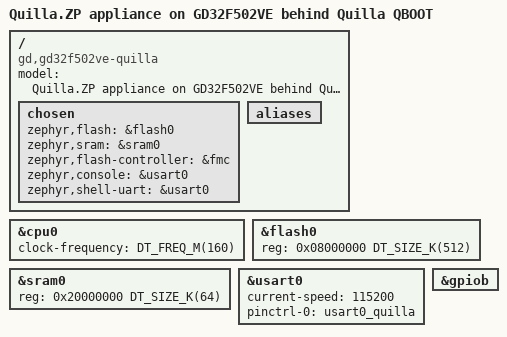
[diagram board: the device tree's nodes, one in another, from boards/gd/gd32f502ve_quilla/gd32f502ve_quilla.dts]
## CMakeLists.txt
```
# Copyright (c) 2026, JiChiRen Info. Tech.
# All rights reserved.
#
# Redistribution and use in source and binary forms, with or without
# modification, are permitted provided that the conditions of the BSD-3
# license referenced in the project LICENSE file are met.

cmake_minimum_required(VERSION 3.20.0)

find_package(Zephyr REQUIRED HINTS $ENV{ZEPHYR_BASE})
project(quilla_zp LANGUAGES C)

# Each Quilla-side capability is a separate translation unit registered
# through Zephyr's own mechanisms (SHELL_CMD_REGISTER, SYS_INIT, Kconfig,
# devicetree). Nothing is added to the upstream Zephyr tree.
target_sources(app PRIVATE
  src/main.c
  src/quilla_shell.c
  src/quilla_meta.c
  src/quilla_secver.c
  src/led.c
)

# quilla-version.h is the single source for the signed security version
# (QUILLA_APP_SECURITY_VERSION) and the QAV1 magic; it lives in the Quilla
# subtree shipped alongside this appliance. No Zephyr Kconfig knob for the
# version: override it per build with -DQUILLA_APP_SECURITY_VERSION=<n>.
target_include_directories(app PRIVATE
  src
  ${CMAKE_CURRENT_SOURCE_DIR}/../quilla/os/sys
)

# The QAV1 security-version record must sit at a fixed flash address because
# QBOOT reads it without a symbol table. A ROM_START linker snippet is the
# standard Zephyr way to reserve that slot; see app/linker/quilla-secver.ld.
# SORT_KEY places it after Zephyr's own vector-table snippets.
zephyr_linker_sources(ROM_START SORT_KEY 0x3secver linker/quilla-secver.ld)
```

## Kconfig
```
# Copyright (c) 2026, JiChiRen Info. Tech.
# All rights reserved.
# SPDX-License-Identifier: BSD-3-Clause

menu "Quilla.ZP appliance"

# The firmware security version is NOT configured here: it comes from the
# shared Quilla header quilla/os/sys/quilla-version.h as
# QUILLA_APP_SECURITY_VERSION (overridable per build with a -D define), so
# QAPP, QBOOT and this appliance all use one version source.

config QUILLA_ZP_APP_NAME
	string "Application name printed in the [QAPP] banner"
	default "Quilla.ZP"

config QUILLA_ZP_APP_VERSION
	string "Application version string"
	default "V1.0.0001"

config QUILLA_ZP_META_BASE
	hex "META region base address"
	default 0x08006000

config QUILLA_ZP_META_SIZE
	hex "META region size"
	default 0x1000

config QUILLA_ZP_APP_START
	hex "APP region base address"
	default 0x08007000

config QUILLA_ZP_SECVER_OFFSET
	hex "Security-version record offset from APP start"
	default 0x400

config QUILLA_ZP_LED_BEAT_MS
	int "LED heart-beat period in milliseconds (0 disables)"
	default 1000

endmenu

# An application Kconfig replaces the Zephyr root Kconfig, so the upstream
# tree must be sourced explicitly. Without this line no CONFIG_* symbol
# outside this file exists and the build aborts with "undefined symbol".
source "Kconfig.zephyr"
```

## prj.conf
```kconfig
# Copyright (c) 2026, JiChiRen Info. Tech.
# All rights reserved.
# SPDX-License-Identifier: BSD-3-Clause
#
# Quilla.ZP application configuration.

# ---- Console / Quilla APP shell -------------------------------------------
# The console UART is chosen in app/boards/gd/gd32f502ve_quilla/*.dts; it is
# USART0 / PB6-PB7 / 115200, the same wiring QBOOT uses on this board.
CONFIG_CONSOLE=y
CONFIG_UART_CONSOLE=y
CONFIG_SERIAL=y
CONFIG_SHELL=y
CONFIG_SHELL_BACKEND_SERIAL=y
# The Quilla host updater probes with a bare "part" line and matches "app1"
# in the reply. A plain prompt keeps the line parser free of ANSI escapes.
CONFIG_SHELL_PROMPT_UART="> "
CONFIG_SHELL_VT100_COLORS=n
CONFIG_SHELL_VT100_COMMANDS=n
CONFIG_SHELL_WILDCARD=n
CONFIG_SHELL_HISTORY=n

# ---- Flash driver (META record writer) ------------------------------------
CONFIG_FLASH=y

# ---- GPIO / LED heart-beat -------------------------------------------------
CONFIG_GPIO=y

# ---- Boot handover ---------------------------------------------------------
# Quilla QBOOT owns the boot policy. The APP vector table must be at
# 0x08007000 exactly (QBOOT reads MSP/reset from there and sets VTOR), so
# link with an explicit flash offset and reserve no image header.
CONFIG_BOOTLOADER_MCUBOOT=n
CONFIG_ROM_START_OFFSET=0
CONFIG_USE_DT_CODE_PARTITION=n
CONFIG_FLASH_LOAD_OFFSET=0x7000
CONFIG_FLASH_LOAD_SIZE=0x79000
# The QAV1 linker snippet is injected via snippets-rom-start.ld, which is
# consumed by the LD template path (the CMake linker generator does not
# include it). Pin the template so the section cannot silently disappear.
CONFIG_LD_LINKER_TEMPLATE=y

# ---- Runtime ---------------------------------------------------------------
CONFIG_MAIN_STACK_SIZE=2048
CONFIG_PRINTK=y
# sys_reboot() is only compiled when CONFIG_REBOOT is set (lib/os/Kconfig).
CONFIG_REBOOT=y
CONFIG_LOG=n
```

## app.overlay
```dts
/*
 * Copyright (c) 2026, JiChiRen Info. Tech.
 * All rights reserved.
 * SPDX-License-Identifier: BSD-3-Clause
 *
 * Optional board wiring that is not part of the QBOOT contract.
 *
 * The QBOOT console (USART0 / PB6-PB7 / 115200), the flash geometry and the
 * core clock are fixed in the out-of-tree board definition under
 * app/boards/gd/gd32f502ve_quilla/. Nothing here may change them.
 *
 * To enable the LED heart-beat thread, add a led0 alias matching the LED on
 * the actual board, for example:
 *
 *   / {
 *       leds {
 *           compatible = "gpio-leds";
 *           led0: led_0 {
 *               gpios = <&gpiob 2 GPIO_ACTIVE_LOW>;
 *               label = "User LED";
 *           };
 *       };
 *
 *       aliases { led0 = &led0; };
 *   };
 *
 * Without led0 the application still builds and runs: the shell and the
 * QIAP handover remain fully available, and the LED thread is not created.
 */

/* Keep the overlay a valid devicetree fragment even when nothing is added. */
/ {
};
```

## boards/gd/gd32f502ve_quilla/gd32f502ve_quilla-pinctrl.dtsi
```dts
/*
 * Copyright (c) 2026, JiChiRen Info. Tech.
 * All rights reserved.
 * SPDX-License-Identifier: BSD-3-Clause
 *
 * USART0 remapped to PB6 (TX) / PB7 (RX), AF0 -- identical to QBOOT's
 * arch/cpu/arm/gd32f502ve/shellport.c binding. The pinmux macros come from
 * the hal_gigadevice module pulled by `west update`.
 */

#include <dt-bindings/pinctrl/gd32f503v(g-e-c)xx-pinctrl.h>

&pinctrl {
	usart0_quilla: usart0_quilla {
		group1 {
			pinmux = <USART0_TX_PB6>, <USART0_RX_PB7>;
			bias-pull-up;
		};
	};
};
```

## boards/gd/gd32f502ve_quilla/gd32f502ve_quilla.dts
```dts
/*
 * Copyright (c) 2026, JiChiRen Info. Tech.
 * All rights reserved.
 * SPDX-License-Identifier: BSD-3-Clause
 *
 * Out-of-tree board for the GD32F502VE target used by Quilla QBOOT.
 * The upstream gd32f50x SoC description is reused; this file overrides the
 * part-specific flash/SRAM sizes and the core clock, and binds the console
 * to the same USART0 / PB6-PB7 / 115200 wiring QBOOT uses.
 */

/dts-v1/;

#include <gd/gd32f50x/gd32f503vg.dtsi>
#include "gd32f502ve_quilla-pinctrl.dtsi"

/ {
	model = "Quilla.ZP appliance on GD32F502VE behind Quilla QBOOT";
	compatible = "gd,gd32f502ve-quilla";

	chosen {
		zephyr,flash = &flash0;
		zephyr,sram = &sram0;
		zephyr,flash-controller = &fmc;
		zephyr,console = &usart0;
		zephyr,shell-uart = &usart0;
	};

	aliases {
		/* led0 is intentionally not defined here: the reference board's LED
		 * pin is not part of the QBOOT contract. Add a led0 alias in
		 * app.overlay to enable the heart-beat thread. */
	};
};

/* GD32F502VE: 512 KiB Flash / 64 KiB SRAM, 160 MHz (8 MHz HXTAL -> PLL).
 * QBOOT leaves the RCC configured at 160 MHz when it jumps; declaring the
 * same frequency here keeps Zephyr's clock driver and UART baud derivation
 * consistent with the inherited clock tree. */
&cpu0 {
	clock-frequency = <DT_FREQ_M(160)>;
};

&flash0 {
	reg = <0x08000000 DT_SIZE_K(512)>;
};

&sram0 {
	reg = <0x20000000 DT_SIZE_K(64)>;
};

&usart0 {
	status = "okay";
	current-speed = <115200>;
	pinctrl-0 = <&usart0_quilla>;
	pinctrl-names = "default";
};

&gpiob {
	status = "okay";
};
```

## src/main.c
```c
/*
 * Copyright (c) 2026, JiChiRen Info. Tech.
 * All rights reserved.
 *
 * Redistribution and use in source and binary forms, with or without
 * modification, are permitted provided that the conditions of the BSD-3
 * license referenced in the project LICENSE file are met.
 *
 * This file is part of the Quilla.ZP appliance.
 */

#include <zephyr/kernel.h>

/*
 * Intentionally minimal. Every capability of this appliance is registered by
 * Zephyr itself:
 *
 *   quilla_shell.c  SHELL_CMD_REGISTER (part / version / swqboot)
 *                   SYS_INIT           (banner)
 *   led.c           K_THREAD_DEFINE   (LED heart-beat, optional)
 *   quilla_secver.c section attribute + ROM_START linker snippet (QAV1)
 *   quilla_meta.c   flash API, invoked only by the swqboot command
 *
 * main() only keeps the main thread alive; it must not accumulate unrelated
 * features, and it must never include a Quilla header.
 */
int main(void)
{
	while (true) {
		k_sleep(K_SECONDS(60));
	}
}
```

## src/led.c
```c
/*
 * Copyright (c) 2026, JiChiRen Info. Tech.
 * All rights reserved.
 *
 * Redistribution and use in source and binary forms, with or without
 * modification, are permitted provided that the conditions of the BSD-3
 * license referenced in the project LICENSE file are met.
 *
 * This file is part of the Quilla.ZP appliance.
 */

#include <zephyr/device.h>
#include <zephyr/devicetree.h>
#include <zephyr/drivers/gpio.h>
#include <zephyr/kernel.h>

/*
 * Zephyr's static thread registration replaces the Quilla QAPP Contiki
 * process / FreeRTOS task: the LED heart-beat is a K_THREAD_DEFINE entry, and
 * the LED itself comes from the devicetree "led0" alias. Adding an alias in
 * app.overlay is enough to enable the thread; no source change required.
 *
 * This file owns the LED only. It does not touch the console, META or secver.
 */

#if DT_NODE_EXISTS(DT_ALIAS(led0))

static const struct gpio_dt_spec led = GPIO_DT_SPEC_GET(DT_ALIAS(led0), gpios);

static void led_thread(void *unused1, void *unused2, void *unused3)
{
	ARG_UNUSED(unused1);
	ARG_UNUSED(unused2);
	ARG_UNUSED(unused3);

	if (!gpio_is_ready_dt(&led)) {
		return;
	}
	if (gpio_pin_configure_dt(&led, GPIO_OUTPUT_ACTIVE) != 0) {
		return;
	}

	while (true) {
		gpio_pin_toggle_dt(&led);
		k_msleep(CONFIG_QUILLA_ZP_LED_BEAT_MS);
	}
}

K_THREAD_DEFINE(quilla_zp_led_tid, 512, led_thread, NULL, NULL, NULL,
		K_LOWEST_APPLICATION_THREAD_PRIO, 0, 0);

#endif /* DT_NODE_EXISTS(DT_ALIAS(led0)) */
```

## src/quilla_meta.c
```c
/*
 * Copyright (c) 2026, JiChiRen Info. Tech.
 * All rights reserved.
 *
 * Redistribution and use in source and binary forms, with or without
 * modification, are permitted provided that the conditions of the BSD-3
 * license referenced in the project LICENSE file are met.
 *
 * This file is part of the Quilla.ZP appliance.
 */

#include "quilla_meta.h"

#include <errno.h>
#include <string.h>

#include <zephyr/device.h>
#include <zephyr/devicetree.h>
#include <zephyr/drivers/flash.h>
#include <zephyr/kernel.h>
#include <zephyr/sys/util.h>

/*
 * APP-side META writer. QBOOT owns the boot policy; the appliance is only
 * allowed to append one record changing the interaction flag. Every field
 * that belongs to QBOOT (manifest, seal, anti-rollback floor) is inherited
 * unchanged, so an upgrade request cannot erase the factory manifest.
 *
 * The record layout, magics and CRC are binary-compatible with
 * quilla-qboot-meta.c. No Quilla header is included: the two images share
 * only a flash contract.
 */

#define QZP_META_RECORD_SIZE 256U
#define QZP_META_SLOT_SIZE   (CONFIG_QUILLA_ZP_META_SIZE / 2U)
#define QZP_META_SLOTS       2U
#define QZP_REC_PER_SLOT     (QZP_META_SLOT_SIZE / QZP_META_RECORD_SIZE)

#define QZP_META_BLK_MAGIC  0x514D544CU /* "QMTL" */
#define QZP_MANI_BLK_MAGIC  0x514D4631U /* "QMF1" */
#define QZP_MANI_BLK_OFF    64U
#define QZP_MANI_BLK_SIZE   128U

#define QZP_OFF_MAGIC       0U
#define QZP_OFF_SEQ         4U
#define QZP_OFF_FLAG        8U
#define QZP_OFF_FLOOR       12U
#define QZP_OFF_CRC         52U

#define QZP_MANI_OFF_MAGIC     0U
#define QZP_MANI_OFF_VERSION   4U
#define QZP_MANI_OFF_IMAGE_LEN 8U
#define QZP_MANI_OFF_CRC       108U

/* The GD32 bank0 erase page is 2 KiB, i.e. exactly one META slot. QBOOT never
 * erases the active slot; only the standby slot is erased. */
#define QZP_ERASE_PAGE_SIZE 2048U

BUILD_ASSERT(QZP_META_SLOT_SIZE == QZP_ERASE_PAGE_SIZE,
	     "META slot must equal one GD32 flash erase page");
BUILD_ASSERT((CONFIG_QUILLA_ZP_META_BASE % QZP_ERASE_PAGE_SIZE) == 0,
	     "META base must be erase-page aligned");

static const struct device *const flash_dev =
	DEVICE_DT_GET(DT_CHOSEN(zephyr_flash_controller));

/* uint32_t storage keeps the programming buffer naturally aligned for the
 * GD32 FMC word-program path. */
static uint32_t s_best_words[QZP_META_RECORD_SIZE / 4U];
static uint32_t s_work_words[QZP_META_RECORD_SIZE / 4U];

static uint32_t rd32(const uint8_t *p)
{
	return (uint32_t)p[0] | ((uint32_t)p[1] << 8) |
	       ((uint32_t)p[2] << 16) | ((uint32_t)p[3] << 24);
}

static void wr32(uint8_t *p, uint32_t v)
{
	p[0] = (uint8_t)(v >> 0);
	p[1] = (uint8_t)(v >> 8);
	p[2] = (uint8_t)(v >> 16);
	p[3] = (uint8_t)(v >> 24);
}

/* IEEE 802.3 CRC-32, reflected polynomial 0xEDB88320. Bit-identical to
 * QBOOT's meta_crc32 and to Zephyr's crc32_ieee(); implemented locally so the
 * appliance does not depend on the CRC Kconfig driver selection. */
static uint32_t crc32_ieee(const uint8_t *p, uint32_t len)
{
	uint32_t crc = 0xFFFFFFFFU;

	for (uint32_t i = 0U; i < len; i++) {
		crc ^= p[i];
		for (uint32_t j = 0U; j < 8U; j++) {
			crc = (crc & 1U) ? ((crc >> 1U) ^ 0xEDB88320U) : (crc >> 1U);
		}
	}
	return crc ^ 0xFFFFFFFFU;
}

/* Zephyr flash API offsets are relative to the flash base, while the QBOOT
 * partition constants are absolute addresses. */
static off_t flash_offset(uint32_t abs_addr)
{
	return (off_t)(abs_addr - DT_REG_ADDR(DT_CHOSEN(zephyr_flash)));
}

static int meta_read(uint32_t abs_addr, uint8_t *dst, size_t len)
{
	return flash_read(flash_dev, flash_offset(abs_addr), dst, len);
}

static int meta_erase_slot(uint32_t abs_addr)
{
	return flash_erase(flash_dev, flash_offset(abs_addr), QZP_META_SLOT_SIZE);
}

static uint32_t record_seq(uint32_t abs_addr, uint8_t *scratch)
{
	if (meta_read(abs_addr, scratch, QZP_META_RECORD_SIZE) != 0) {
		return 0U;
	}
	if (rd32(scratch + QZP_OFF_MAGIC) != QZP_META_BLK_MAGIC) {
		return 0U;
	}
	if (crc32_ieee(scratch, QZP_OFF_CRC) != rd32(scratch + QZP_OFF_CRC)) {
		return 0U;
	}
	/* seq 0 is the "empty record" sentinel. */
	return rd32(scratch + QZP_OFF_SEQ);
}

static bool manifest_valid(const uint8_t *rec)
{
	const uint8_t *p = rec + QZP_MANI_BLK_OFF;

	if (rd32(p + QZP_MANI_OFF_MAGIC) != QZP_MANI_BLK_MAGIC) {
		return false;
	}
	return crc32_ieee(p, QZP_MANI_OFF_CRC) == rd32(p + QZP_MANI_OFF_CRC);
}

static void build_empty_manifest(uint8_t *rec)
{
	uint8_t *p = rec + QZP_MANI_BLK_OFF;

	memset(p, 0xFFU, QZP_MANI_BLK_SIZE);
	wr32(p + QZP_MANI_OFF_MAGIC, QZP_MANI_BLK_MAGIC);
	wr32(p + QZP_MANI_OFF_VERSION, 0U);
	wr32(p + QZP_MANI_OFF_IMAGE_LEN, 0U);
	wr32(p + QZP_MANI_OFF_CRC, crc32_ieee(p, QZP_MANI_OFF_CRC));
}

static bool region_erased(uint32_t abs_addr, size_t len)
{
	uint8_t buf[QZP_META_RECORD_SIZE];

	if (meta_read(abs_addr, buf, len) != 0) {
		return false;
	}
	for (size_t i = 0U; i < len; i++) {
		if (buf[i] != 0xFFU) {
			return false;
		}
	}
	return true;
}

int quilla_zp_meta_set_flag(uint32_t flag)
{
	uint8_t *best = (uint8_t *)s_best_words;
	uint8_t *work = (uint8_t *)s_work_words;
	uint32_t head[QZP_META_SLOTS] = { 0U, 0U };
	uint32_t best_seq = 0U;
	uint8_t best_slot = 0U;
	bool found = false;
	uint32_t slot_base;
	uint32_t target;
	uint32_t new_seq;
	int rc;

	if (!device_is_ready(flash_dev)) {
		return -ENODEV;
	}

	/* Scan both slots; the highest sequence is authoritative. */
	for (uint8_t slot = 0U; slot < QZP_META_SLOTS; slot++) {
		for (uint32_t idx = 0U; idx < QZP_REC_PER_SLOT; idx++) {
			uint32_t addr = CONFIG_QUILLA_ZP_META_BASE +
					((uint32_t)slot * QZP_META_SLOT_SIZE) +
					(idx * QZP_META_RECORD_SIZE);
			uint32_t seq = record_seq(addr, work);

			if (seq == 0U) {
				break;
			}
			head[slot] = idx + 1U;
			if (!found || (seq > best_seq)) {
				best_seq = seq;
				best_slot = slot;
				found = true;
				memcpy(best, work, QZP_META_RECORD_SIZE);
			}
		}
	}

	uint8_t active = found ? best_slot : 0U;
	new_seq = best_seq + 1U; /* empty store -> first record has seq 1 */

	/* Active slot full, or its write head is not blank: switch to the
	 * standby slot and erase it. The authoritative record lives in the
	 * other slot, so a power loss here cannot destroy the only copy. */
	bool switch_needed = head[active] >= QZP_REC_PER_SLOT;
	if (!switch_needed) {
		slot_base = CONFIG_QUILLA_ZP_META_BASE +
			    ((uint32_t)active * QZP_META_SLOT_SIZE);
		target = slot_base + head[active] * QZP_META_RECORD_SIZE;
		switch_needed = !region_erased(target, QZP_META_RECORD_SIZE);
	}
	if (switch_needed) {
		uint8_t other = (uint8_t)(1U - (uint32_t)active);

		rc = meta_erase_slot(CONFIG_QUILLA_ZP_META_BASE +
				     ((uint32_t)other * QZP_META_SLOT_SIZE));
		if (rc != 0) {
			return rc;
		}
		active = other;
		head[active] = 0U;
	}

	slot_base = CONFIG_QUILLA_ZP_META_BASE +
		    ((uint32_t)active * QZP_META_SLOT_SIZE);
	target = slot_base + head[active] * QZP_META_RECORD_SIZE;

	/* Compose the record: inherit every field, change only seq and flag. */
	if (found) {
		memcpy(work, best, QZP_META_RECORD_SIZE);
	} else {
		memset(work, 0xFFU, QZP_META_RECORD_SIZE);
		memset(work + QZP_OFF_FLOOR, 0U, QZP_OFF_CRC - QZP_OFF_FLOOR);
	}
	wr32(work + QZP_OFF_MAGIC, QZP_META_BLK_MAGIC);
	wr32(work + QZP_OFF_SEQ, new_seq);
	wr32(work + QZP_OFF_FLAG, flag);
	wr32(work + QZP_OFF_CRC, crc32_ieee(work, QZP_OFF_CRC));

	if (!found || !manifest_valid(work)) {
		build_empty_manifest(work);
	}

	/* Program-only append into erased cells; no erase of the active slot. */
	rc = flash_write(flash_dev, flash_offset(target), work,
			 QZP_META_RECORD_SIZE);
	if (rc != 0) {
		return rc;
	}

	/* Re-read using QBOOT's own acceptance rules. */
	if (record_seq(target, best) != new_seq) {
		return -EIO;
	}
	if (rd32(best + QZP_OFF_FLAG) != flag) {
		return -EIO;
	}
	return 0;
}
```

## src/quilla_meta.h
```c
/*
 * Copyright (c) 2026, JiChiRen Info. Tech.
 * All rights reserved.
 *
 * Redistribution and use in source and binary forms, with or without
 * modification, are permitted provided that the conditions of the BSD-3
 * license referenced in the project LICENSE file are met.
 *
 * This file is part of the Quilla.ZP appliance.
 */

#ifndef QUILLA_ZP_META_H_
#define QUILLA_ZP_META_H_

#include <stdint.h>

/* Values are defined by Quilla's quilla-qboot-flag.h. They are duplicated
 * here (not included) so the appliance has no Quilla header dependency. */
#define QUILLA_ZP_FLAG_APP1  0x00000001U
#define QUILLA_ZP_FLAG_QIAP  0x00000002U
#define QUILLA_ZP_FLAG_QBOOT 0x00000003U

/*
 * Append a META record carrying the requested flag, keeping the manifest,
 * seal and anti-rollback floor inherited from the newest valid record.
 * Returns 0 on success, negative errno on flash failure. A failure is a
 * failed commit: the caller must NOT reboot into the upgrade.
 */
int quilla_zp_meta_set_flag(uint32_t flag);

#endif /* QUILLA_ZP_META_H_ */
```

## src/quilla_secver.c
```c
/*
 * Copyright (c) 2026, JiChiRen Info. Tech.
 * All rights reserved.
 *
 * Redistribution and use in source and binary forms, with or without
 * modification, are permitted provided that the conditions of the BSD-3
 * license referenced in the project LICENSE file are met.
 *
 * This file is part of the Quilla.ZP appliance.
 */

#include "quilla_secver.h"
#include "quilla-version.h"

#include <zephyr/toolchain.h>

/*
 * Owns the QAV1 region and nothing else. The section name is consumed by
 * app/linker/quilla-secver.ld. Both the magic and the version come from the
 * shared Quilla header (single source for QAPP, QBOOT and this appliance);
 * the version is never supplied by the host updater.
 */
const quilla_zp_secver_t quilla_zp_secver
	Z_GENERIC_SECTION(.quilla_secver) __used = {
	.magic = QUILLA_APP_SECVER_MAGIC_U32,
	.version = QUILLA_APP_SECURITY_VERSION,
};
```

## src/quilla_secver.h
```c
/*
 * Copyright (c) 2026, JiChiRen Info. Tech.
 * All rights reserved.
 *
 * Redistribution and use in source and binary forms, with or without
 * modification, are permitted provided that the conditions of the BSD-3
 * license referenced in the project LICENSE file are met.
 *
 * This file is part of the Quilla.ZP appliance.
 */

#ifndef QUILLA_ZP_SECVER_H_
#define QUILLA_ZP_SECVER_H_

#include <stdint.h>

/*
 * QBOOT's anti-rollback gate reads an 8-byte record at a FIXED flash address
 * (APP_START + 0x400) without any symbol table. The layout below is defined
 * locally in the appliance: including any Quilla header here would couple the
 * two images.
 *
 * This record sits inside the signed image, so its version cannot be changed
 * without the private key.
 */
/* The magic and version values come from the shared Quilla header
 * quilla-version.h (QUILLA_APP_SECVER_MAGIC_U32 / QUILLA_APP_SECURITY_VERSION),
 * included by quilla_secver.c; only the record layout is declared locally so
 * the appliance stays independent of Quilla's headers for its type
 * definitions. */

typedef struct {
	uint32_t magic;
	uint32_t version;
} quilla_zp_secver_t;

/*
 * Zephyr-native placement: the variable is emitted into a dedicated input
 * section, and app/linker/quilla-secver.ld (registered through
 * zephyr_linker_sources(ROM_START ...)) pins that section to the absolute
 * address QBOOT reads. Do not move this definition into main.c.
 */
extern const quilla_zp_secver_t quilla_zp_secver;

#endif /* QUILLA_ZP_SECVER_H_ */
```

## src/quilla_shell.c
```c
/*
 * Copyright (c) 2026, JiChiRen Info. Tech.
 * All rights reserved.
 *
 * Redistribution and use in source and binary forms, with or without
 * modification, are permitted provided that the conditions of the BSD-3
 * license referenced in the project LICENSE file are met.
 *
 * This file is part of the Quilla.ZP appliance.
 */

#include "quilla_meta.h"

#include <errno.h>

#include <zephyr/init.h>
#include <zephyr/kernel.h>
#include <zephyr/shell/shell.h>
#include <zephyr/sys/printk.h>
#include <zephyr/sys/reboot.h>

/*
 * The Quilla APP shell, registered as a Zephyr shell command set. The host
 * updater talks to this text protocol: it probes with "part" and expects a
 * line containing "app1", then sends "swqboot" to park the device in QBOOT.
 *
 * Zephyr's own shell already provides "help" and "kernel"; Quilla's shell
 * provides "part", "kernel" and registered APP commands. Only the two
 * protocol-facing commands are added here, each with SHELL_CMD_REGISTER.
 */

static int cmd_part(const struct shell *sh, size_t argc, char **argv)
{
	ARG_UNUSED(argc);
	ARG_UNUSED(argv);

	shell_print(sh, "app1");
	return 0;
}

static int cmd_version(const struct shell *sh, size_t argc, char **argv)
{
	ARG_UNUSED(argc);
	ARG_UNUSED(argv);

	shell_print(sh, "[QAPP] " CONFIG_QUILLA_ZP_APP_NAME " "
			 CONFIG_QUILLA_ZP_APP_VERSION);
	return 0;
}

static int cmd_swqboot(const struct shell *sh, size_t argc, char **argv)
{
	int rc;

	ARG_UNUSED(argc);
	ARG_UNUSED(argv);

	/* This literal is extracted from the image by the host updater as the
	 * post-upgrade boot stamp candidate; keep it as a complete string. */
	shell_print(sh, "[QAPP] switching to QBOOT...");

	rc = quilla_zp_meta_set_flag(QUILLA_ZP_FLAG_QBOOT);
	if (rc != 0) {
		shell_error(sh, "META flag commit failed (%d); staying in APP", rc);
		return -EIO;
	}

	/* Let the line reach the host before the UART is shut down by reset. */
	k_msleep(20);
	sys_reboot(SYS_REBOOT_COLD);
	return 0;
}

SHELL_CMD_REGISTER(part, NULL, "Show partition identity", cmd_part);
SHELL_CMD_REGISTER(version, NULL, "Show appliance version", cmd_version);
SHELL_CMD_REGISTER(swqboot, NULL, "Switch to QBOOT for an upgrade", cmd_swqboot);

/* Print at POST_KERNEL, before the serial shell backend (APPLICATION level)
 * takes over the UART, so the banner arrives as one clean line. Registered
 * through SYS_INIT rather than called from main(): the console and the shell
 * are separate Zephyr subsystems and must not depend on the app thread. */
static int quilla_zp_banner(void)
{
	printk("[QAPP] " CONFIG_QUILLA_ZP_APP_NAME " "
	       CONFIG_QUILLA_ZP_APP_VERSION "\n");
	return 0;
}

SYS_INIT(quilla_zp_banner, POST_KERNEL, 99);
```
